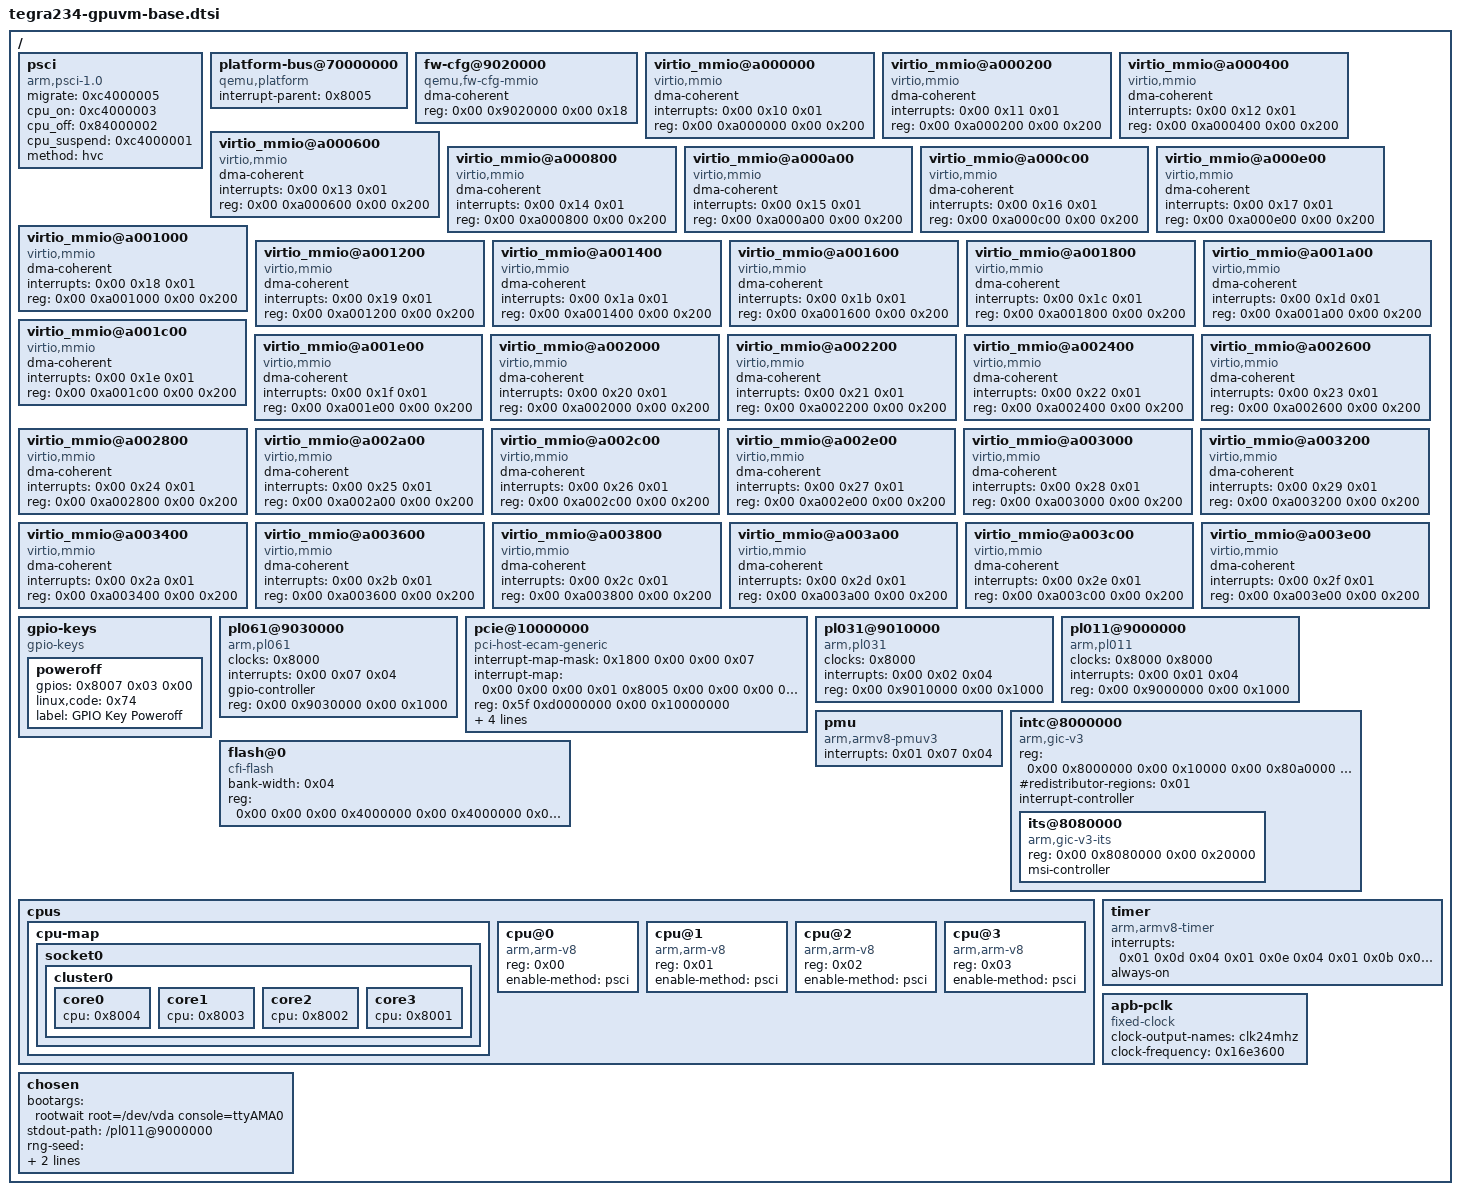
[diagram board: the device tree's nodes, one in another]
// SPDX-License-Identifier: GPL-2.0-only
// SPDX-FileCopyrightText: Copyright (c) 2023, NVIDIA CORPORATION & AFFILIATES.  All rights reserved.
// QEMU virt machine infrastructure: PSCI, CPUs, GIC, UART, virtio,
// and the platform-bus node whose ranges translate passed-through
// device MMIO to guest addresses. Devices live in the sibling .dtsi
// fragments and re-open platform-bus@70000000.

/ {
	psci {
		migrate = <0xc4000005>;
		cpu_on = <0xc4000003>;
		cpu_off = <0x84000002>;
		cpu_suspend = <0xc4000001>;
		method = "hvc";
		compatible = "arm,psci-1.0\0arm,psci-0.2\0arm,psci";
	};

	platform-bus@70000000 {
		interrupt-parent = <0x8005>;

		// QEMU does not map 1:1 the platform devices, so we have to define the
		// address translation here.
		// To get the address of the devices run in the QEMU console: info mtree -f
		//        From            To              Size
		ranges =
#ifndef EXP_DROP_GPU
				 <0x00 0x17000000 0x00 0x64000000 0x00 0x01000000>,     // 0x64000000-0000000064ffffff (prio 0, ramd): VFIO 17000000.gpu region 0
				 <0x00 0x18000000 0x00 0x65000000 0x00 0x01000000>,     // 0x65000000-0000000065ffffff (prio 0, ramd): VFIO 17000000.gpu region 1
				 <0x00 0x03b41000 0x00 0x66000000 0x00 0x00001000>,     // 0x66000000-0000000066000fff (prio 0, ramd): VFIO 17000000.gpu region 2
#endif
				 <0x00 0x03810000 0x00 0x80000000 0x00 0x00010000>,     // Dummy address for fuse

				 // display window 0x66200000: NOT a full VFIO display device. Only two
				 // keyholes are vfio-backed inside it: 13830000.disp_caps_pt at guest
				 // 0x66230000 and 13870000.disp_chan_pt at guest 0x66270000; the rest
				 // of nvdisplay/dpaux/hdacodec/mipical is unbacked address space.
				 <0x00 0x13800000 0x00 0x66200000 0x00 0x000EFFFF>,     // nvdisplay window
				 <0x00 0x155C0000 0x00 0x660e0000 0x00 0x0000FFFF>,     // dpaux0 window
				 <0x00 0x0242c000 0x00 0x66001000 0x00 0x00001000>,     // hdacodec window
				 <0x00 0x03990000 0x00 0x660f0000 0x00 0x00010000>,     // mipical window

				 // historic DCE MMIO window, no vfio backing: the real DCE R5 is
				 // host-owned and guest DCE traffic uses the proxy window at
				 // 0x090e0000 (see tegra234-gpuvm-proxies.dtsi)
				 <0x00 0x0d800000 0x00 0x66800000 0x00 0x00800000>
#ifndef EXP_DROP_HOST1X
				 ,<0x00 0x13e00000 0x00 0x66010000 0x00 0x00010000>     // 0x66010000-000000006601ffff (prio 0, ramd): VFIO 13e00000.host1x_pt region 0
				 ,<0x00 0x13e10000 0x00 0x66020000 0x00 0x00010000>     // 0x66020000-000000006602ffff (prio 0, ramd): VFIO 13e00000.host1x_pt region 1
				 ,<0x00 0x13e40000 0x00 0x66030000 0x00 0x00010000>     // 0x66030000-000000006603ffff (prio 0, ramd): VFIO 13e00000.host1x_pt region 2
				 ,<0x00 0x13ef0000 0x00 0x66080000 0x00 0x00060000>     // 0x66080000-00000000660dffff (prio 0, ramd): VFIO 13e00000.host1x_pt region 3
				 ,<0x00 0x15340000 0x00 0x66040000 0x00 0x00040000>     // 0x66040000-000000006607ffff (prio 0, ramd): VFIO 15340000.vic region 0
				 ,<0x00 0x15480000 0x00 0x66100000 0x00 0x00040000>     // 0x66100000-000000006613ffff (prio 0, ramd): VFIO 15480000.nvdec region 0
				 ,<0x00 0x15540000 0x00 0x66140000 0x00 0x00040000>     // 0x66140000-000000006617ffff (prio 0, ramd): VFIO 15540000.nvjpg region 0
#endif
				 ;


		#address-cells = <0x02>;
		#size-cells = <0x02>;
		compatible = "qemu,platform\0simple-bus";

		// Here are defined the passthrough devices
		// The commented properties are not needed for the passthrough,
		// or are not supported, because the dependency is not passed through
		// to the VM, for instance the iommus.
	};

	fw-cfg@9020000 {
		dma-coherent;
		reg = <0x00 0x9020000 0x00 0x18>;
		compatible = "qemu,fw-cfg-mmio";
	};

	virtio_mmio@a000000 {
		dma-coherent;
		interrupts = <0x00 0x10 0x01>;
		reg = <0x00 0xa000000 0x00 0x200>;
		compatible = "virtio,mmio";
	};

	virtio_mmio@a000200 {
		dma-coherent;
		interrupts = <0x00 0x11 0x01>;
		reg = <0x00 0xa000200 0x00 0x200>;
		compatible = "virtio,mmio";
	};

	virtio_mmio@a000400 {
		dma-coherent;
		interrupts = <0x00 0x12 0x01>;
		reg = <0x00 0xa000400 0x00 0x200>;
		compatible = "virtio,mmio";
	};

	virtio_mmio@a000600 {
		dma-coherent;
		interrupts = <0x00 0x13 0x01>;
		reg = <0x00 0xa000600 0x00 0x200>;
		compatible = "virtio,mmio";
	};

	virtio_mmio@a000800 {
		dma-coherent;
		interrupts = <0x00 0x14 0x01>;
		reg = <0x00 0xa000800 0x00 0x200>;
		compatible = "virtio,mmio";
	};

	virtio_mmio@a000a00 {
		dma-coherent;
		interrupts = <0x00 0x15 0x01>;
		reg = <0x00 0xa000a00 0x00 0x200>;
		compatible = "virtio,mmio";
	};

	virtio_mmio@a000c00 {
		dma-coherent;
		interrupts = <0x00 0x16 0x01>;
		reg = <0x00 0xa000c00 0x00 0x200>;
		compatible = "virtio,mmio";
	};

	virtio_mmio@a000e00 {
		dma-coherent;
		interrupts = <0x00 0x17 0x01>;
		reg = <0x00 0xa000e00 0x00 0x200>;
		compatible = "virtio,mmio";
	};

	virtio_mmio@a001000 {
		dma-coherent;
		interrupts = <0x00 0x18 0x01>;
		reg = <0x00 0xa001000 0x00 0x200>;
		compatible = "virtio,mmio";
	};

	virtio_mmio@a001200 {
		dma-coherent;
		interrupts = <0x00 0x19 0x01>;
		reg = <0x00 0xa001200 0x00 0x200>;
		compatible = "virtio,mmio";
	};

	virtio_mmio@a001400 {
		dma-coherent;
		interrupts = <0x00 0x1a 0x01>;
		reg = <0x00 0xa001400 0x00 0x200>;
		compatible = "virtio,mmio";
	};

	virtio_mmio@a001600 {
		dma-coherent;
		interrupts = <0x00 0x1b 0x01>;
		reg = <0x00 0xa001600 0x00 0x200>;
		compatible = "virtio,mmio";
	};

	virtio_mmio@a001800 {
		dma-coherent;
		interrupts = <0x00 0x1c 0x01>;
		reg = <0x00 0xa001800 0x00 0x200>;
		compatible = "virtio,mmio";
	};

	virtio_mmio@a001a00 {
		dma-coherent;
		interrupts = <0x00 0x1d 0x01>;
		reg = <0x00 0xa001a00 0x00 0x200>;
		compatible = "virtio,mmio";
	};

	virtio_mmio@a001c00 {
		dma-coherent;
		interrupts = <0x00 0x1e 0x01>;
		reg = <0x00 0xa001c00 0x00 0x200>;
		compatible = "virtio,mmio";
	};

	virtio_mmio@a001e00 {
		dma-coherent;
		interrupts = <0x00 0x1f 0x01>;
		reg = <0x00 0xa001e00 0x00 0x200>;
		compatible = "virtio,mmio";
	};

	virtio_mmio@a002000 {
		dma-coherent;
		interrupts = <0x00 0x20 0x01>;
		reg = <0x00 0xa002000 0x00 0x200>;
		compatible = "virtio,mmio";
	};

	virtio_mmio@a002200 {
		dma-coherent;
		interrupts = <0x00 0x21 0x01>;
		reg = <0x00 0xa002200 0x00 0x200>;
		compatible = "virtio,mmio";
	};

	virtio_mmio@a002400 {
		dma-coherent;
		interrupts = <0x00 0x22 0x01>;
		reg = <0x00 0xa002400 0x00 0x200>;
		compatible = "virtio,mmio";
	};

	virtio_mmio@a002600 {
		dma-coherent;
		interrupts = <0x00 0x23 0x01>;
		reg = <0x00 0xa002600 0x00 0x200>;
		compatible = "virtio,mmio";
	};

	virtio_mmio@a002800 {
		dma-coherent;
		interrupts = <0x00 0x24 0x01>;
		reg = <0x00 0xa002800 0x00 0x200>;
		compatible = "virtio,mmio";
	};

	virtio_mmio@a002a00 {
		dma-coherent;
		interrupts = <0x00 0x25 0x01>;
		reg = <0x00 0xa002a00 0x00 0x200>;
		compatible = "virtio,mmio";
	};

	virtio_mmio@a002c00 {
		dma-coherent;
		interrupts = <0x00 0x26 0x01>;
		reg = <0x00 0xa002c00 0x00 0x200>;
		compatible = "virtio,mmio";
	};

	virtio_mmio@a002e00 {
		dma-coherent;
		interrupts = <0x00 0x27 0x01>;
		reg = <0x00 0xa002e00 0x00 0x200>;
		compatible = "virtio,mmio";
	};

	virtio_mmio@a003000 {
		dma-coherent;
		interrupts = <0x00 0x28 0x01>;
		reg = <0x00 0xa003000 0x00 0x200>;
		compatible = "virtio,mmio";
	};

	virtio_mmio@a003200 {
		dma-coherent;
		interrupts = <0x00 0x29 0x01>;
		reg = <0x00 0xa003200 0x00 0x200>;
		compatible = "virtio,mmio";
	};

	virtio_mmio@a003400 {
		dma-coherent;
		interrupts = <0x00 0x2a 0x01>;
		reg = <0x00 0xa003400 0x00 0x200>;
		compatible = "virtio,mmio";
	};

	virtio_mmio@a003600 {
		dma-coherent;
		interrupts = <0x00 0x2b 0x01>;
		reg = <0x00 0xa003600 0x00 0x200>;
		compatible = "virtio,mmio";
	};

	virtio_mmio@a003800 {
		dma-coherent;
		interrupts = <0x00 0x2c 0x01>;
		reg = <0x00 0xa003800 0x00 0x200>;
		compatible = "virtio,mmio";
	};

	virtio_mmio@a003a00 {
		dma-coherent;
		interrupts = <0x00 0x2d 0x01>;
		reg = <0x00 0xa003a00 0x00 0x200>;
		compatible = "virtio,mmio";
	};

	virtio_mmio@a003c00 {
		dma-coherent;
		interrupts = <0x00 0x2e 0x01>;
		reg = <0x00 0xa003c00 0x00 0x200>;
		compatible = "virtio,mmio";
	};

	virtio_mmio@a003e00 {
		dma-coherent;
		interrupts = <0x00 0x2f 0x01>;
		reg = <0x00 0xa003e00 0x00 0x200>;
		compatible = "virtio,mmio";
	};

	gpio-keys {
		compatible = "gpio-keys";

		poweroff {
			gpios = <0x8007 0x03 0x00>;
			linux,code = <0x74>;
			label = "GPIO Key Poweroff";
		};
	};

	pl061@9030000 {
		phandle = <0x8007>;
		clock-names = "apb_pclk";
		clocks = <0x8000>;
		interrupts = <0x00 0x07 0x04>;
		gpio-controller;
		#gpio-cells = <0x02>;
		compatible = "arm,pl061\0arm,primecell";
		reg = <0x00 0x9030000 0x00 0x1000>;
	};

	pcie@10000000 {
		interrupt-map-mask = <0x1800 0x00 0x00 0x07>;
		interrupt-map = <0x00 0x00 0x00 0x01 0x8005 0x00 0x00 0x00 0x03 0x04 0x00 0x00 0x00 0x02 0x8005 0x00 0x00 0x00 0x04 0x04 0x00 0x00 0x00 0x03 0x8005 0x00 0x00 0x00 0x05 0x04 0x00 0x00 0x00 0x04 0x8005 0x00 0x00 0x00 0x06 0x04 0x800 0x00 0x00 0x01 0x8005 0x00 0x00 0x00 0x04 0x04 0x800 0x00 0x00 0x02 0x8005 0x00 0x00 0x00 0x05 0x04 0x800 0x00 0x00 0x03 0x8005 0x00 0x00 0x00 0x06 0x04 0x800 0x00 0x00 0x04 0x8005 0x00 0x00 0x00 0x03 0x04 0x1000 0x00 0x00 0x01 0x8005 0x00 0x00 0x00 0x05 0x04 0x1000 0x00 0x00 0x02 0x8005 0x00 0x00 0x00 0x06 0x04 0x1000 0x00 0x00 0x03 0x8005 0x00 0x00 0x00 0x03 0x04 0x1000 0x00 0x00 0x04 0x8005 0x00 0x00 0x00 0x04 0x04 0x1800 0x00 0x00 0x01 0x8005 0x00 0x00 0x00 0x06 0x04 0x1800 0x00 0x00 0x02 0x8005 0x00 0x00 0x00 0x03 0x04 0x1800 0x00 0x00 0x03 0x8005 0x00 0x00 0x00 0x04 0x04 0x1800 0x00 0x00 0x04 0x8005 0x00 0x00 0x00 0x05 0x04>;
		#interrupt-cells = <0x01>;
		ranges = <0x1000000 0x00 0x00 0x00 0x3eff0000 0x00 0x10000 0x2000000 0x00 0x10000000 0x00 0x10000000 0x00 0x2eff0000 0x3000000 0x80 0x00 0x80 0x00 0x80 0x00>;
		reg = <0x5f 0xd0000000 0x00 0x10000000>;
		msi-map = <0x00 0x8006 0x00 0x10000>;
		dma-coherent;
		bus-range = <0x00 0xff>;
		linux,pci-domain = <0x00>;
		#size-cells = <0x02>;
		#address-cells = <0x03>;
		device_type = "pci";
		compatible = "pci-host-ecam-generic";
	};

	pl031@9010000 {
		clock-names = "apb_pclk";
		clocks = <0x8000>;
		interrupts = <0x00 0x02 0x04>;
		reg = <0x00 0x9010000 0x00 0x1000>;
		compatible = "arm,pl031\0arm,primecell";
	};

	pl011@9000000 {
		clock-names = "uartclk\0apb_pclk";
		clocks = <0x8000 0x8000>;
		interrupts = <0x00 0x01 0x04>;
		reg = <0x00 0x9000000 0x00 0x1000>;
		compatible = "arm,pl011\0arm,primecell";
	};

	pmu {
		interrupts = <0x01 0x07 0x04>;
		compatible = "arm,armv8-pmuv3";
	};

	intc@8000000 {
		phandle = <0x8005>;
		reg = <0x00 0x8000000 0x00 0x10000 0x00 0x80a0000 0x00 0xf60000>;
		#redistributor-regions = <0x01>;
		compatible = "arm,gic-v3";
		ranges;
		#size-cells = <0x02>;
		#address-cells = <0x02>;
		interrupt-controller;
		#interrupt-cells = <0x03>;

		its@8080000 {
			phandle = <0x8006>;
			reg = <0x00 0x8080000 0x00 0x20000>;
			#msi-cells = <0x01>;
			msi-controller;
			compatible = "arm,gic-v3-its";
		};
	};

	flash@0 {
		bank-width = <0x04>;
		reg = <0x00 0x00 0x00 0x4000000 0x00 0x4000000 0x00 0x4000000>;
		compatible = "cfi-flash";
	};

	cpus {
		#size-cells = <0x00>;
		#address-cells = <0x01>;

		cpu-map {

			socket0 {

				cluster0 {

					core0 {
						cpu = <0x8004>;
					};

					core1 {
						cpu = <0x8003>;
					};

					core2 {
						cpu = <0x8002>;
					};

					core3 {
						cpu = <0x8001>;
					};
				};
			};
		};

		cpu@0 {
			phandle = <0x8004>;
			reg = <0x00>;
			enable-method = "psci";
			compatible = "arm,arm-v8";
			device_type = "cpu";
		};

		cpu@1 {
			phandle = <0x8003>;
			reg = <0x01>;
			enable-method = "psci";
			compatible = "arm,arm-v8";
			device_type = "cpu";
		};

		cpu@2 {
			phandle = <0x8002>;
			reg = <0x02>;
			enable-method = "psci";
			compatible = "arm,arm-v8";
			device_type = "cpu";
		};

		cpu@3 {
			phandle = <0x8001>;
			reg = <0x03>;
			enable-method = "psci";
			compatible = "arm,arm-v8";
			device_type = "cpu";
		};
	};

	timer {
		interrupts = <0x01 0x0d 0x04 0x01 0x0e 0x04 0x01 0x0b 0x04 0x01 0x0a 0x04>;
		always-on;
		compatible = "arm,armv8-timer\0arm,armv7-timer";
	};

	apb-pclk {
		phandle = <0x8000>;
		clock-output-names = "clk24mhz";
		clock-frequency = <0x16e3600>;
		#clock-cells = <0x00>;
		compatible = "fixed-clock";
	};

	chosen {
		bootargs = "rootwait root=/dev/vda console=ttyAMA0";
		stdout-path = "/pl011@9000000";
		rng-seed = <0x67b6f34f 0xc86e63c5 0xa358bcaa 0x4433845d 0xe55d22f3 0xbf39d920 0x8fd3366d 0x15f35a5b>;
		kaslr-seed = <0xca4d66e8 0xda2a6750>;
		#address-cells = <1>;
		#size-cells = <1>;
	};
};
